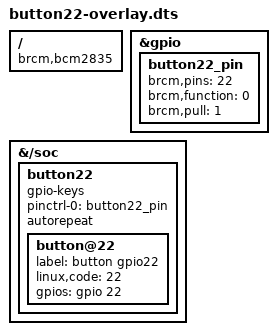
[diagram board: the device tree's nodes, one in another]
/dts-v1/;
/plugin/;

/ {
    compatible = "brcm,bcm2835", "brcm,bcm2708", "brcm,bcm2709";

    fragment@0 {
        target = <&gpio>;
        __overlay__ {
            button22_pin: button22_pin {
                brcm,pins = <22>;     /* gpio22 */
                brcm,function = <0>; /* input */
                brcm,pull = <1>;     /* pull-down */
            };
        };
    };

    fragment@1 {
    target-path = "/soc";
        __overlay__ {
            button22: button22 {
                compatible = "gpio-keys";
                #address-cells = <1>;
                #size-cells = <0>;
                pinctrl-names = "default";
                pinctrl-0 = <&button22_pin>;
                status = "okay";
                autorepeat;

                button@22 {
                    label = "button gpio22";
                    linux,code = <22>;
                    gpios = <&gpio 22 0>;
                };
            };
        };
    };
};

